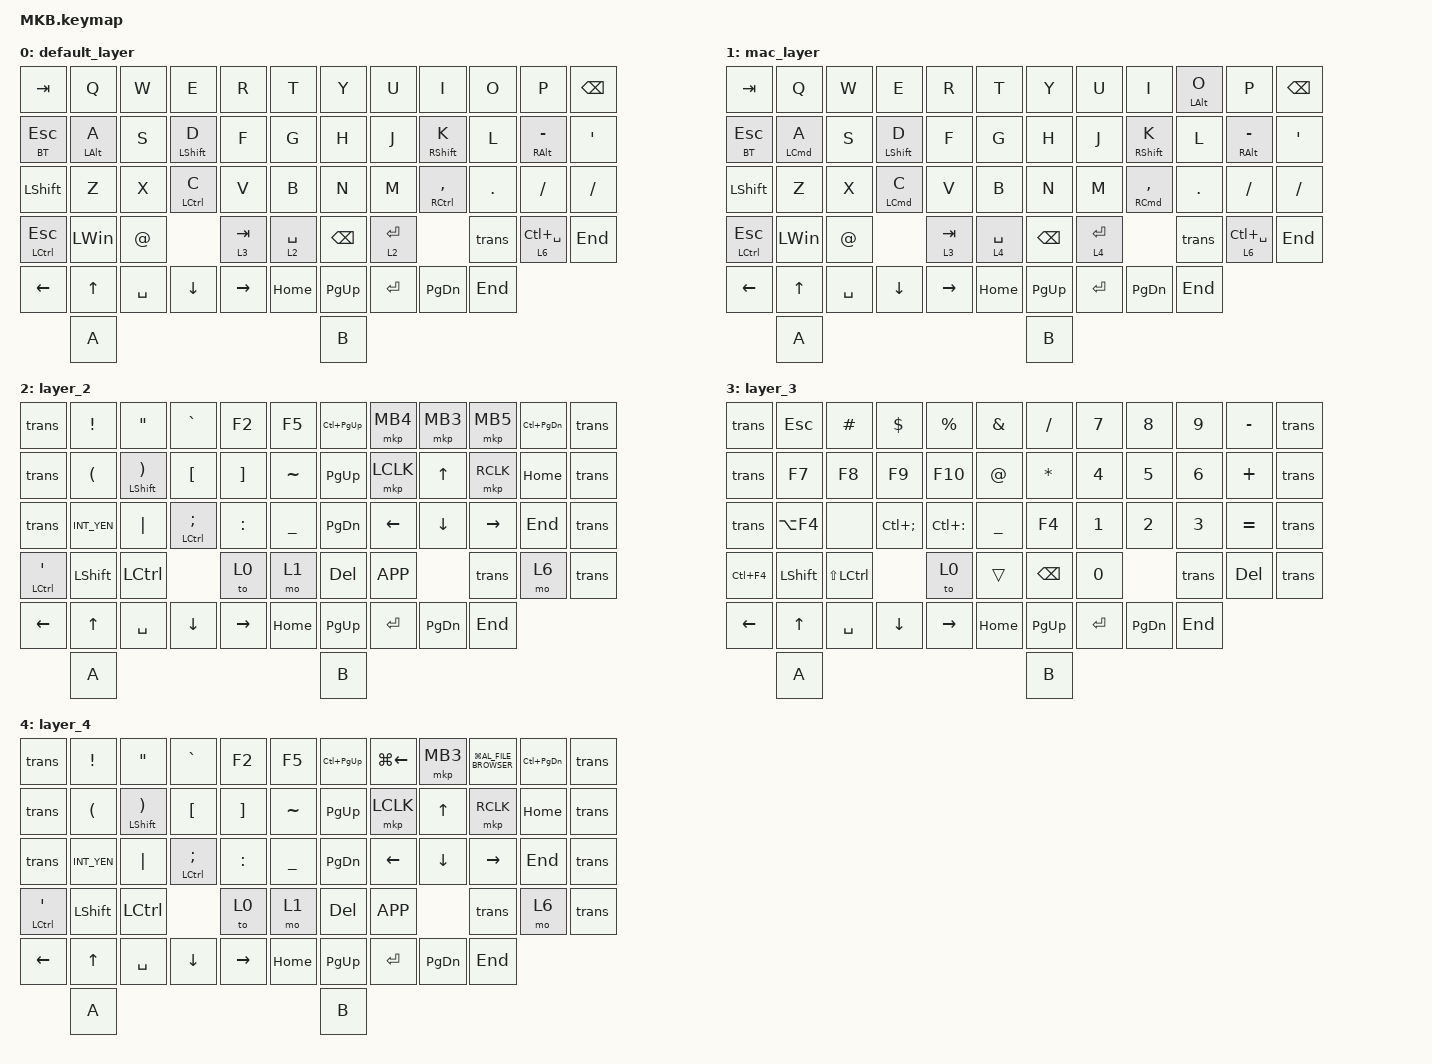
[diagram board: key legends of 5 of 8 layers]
// #include <layout_shift.dtsi>

#include <layout_shift_kp_override.dtsi>
#include <behaviors.dtsi>
#include <dt-bindings/zmk/bt.h>
#include <dt-bindings/zmk/keys.h>
#include <dt-bindings/zmk/pointing.h>
#include <input/processors.dtsi>

// スクロール量を変更

#define ZMK_POINTING_DEFAULT_SCRL_VAL 100
#define MOUSE 5
#define SCROLL 6
#define BT 7

&mt {
    flavor = "balanced";
    quick-tap-ms = <0>;
};

&mkp_input_listener { input-processors = <&zip_temp_layer 5 10000>; };

/ {
    combos { compatible = "zmk,combos"; };

    macros {
        to_layer_0: to_layer_0 {
            compatible = "zmk,behavior-macro-one-param";
            #binding-cells = <1>;
            bindings = <&to 0 &macro_param_1to1 &kp MACRO_PLACEHOLDER>;
            label = "TO_LAYER_0";
        };

        exit_AML: exit_AML {
            compatible = "zmk,behavior-macro";
            wait-ms = <0>;
            tap-ms = <0>;
            #binding-cells = <0>;
            bindings = <&tog_off MOUSE>;
            label = "exit_AML";
        };

        kp_exit_AML: kp_exit_AML {
            compatible = "zmk,behavior-macro-one-param";
            wait-ms = <0>;
            tap-ms = <0>;
            #binding-cells = <1>;
            bindings = <&macro_param_1to1 &kp MACRO_PLACEHOLDER &exit_AML>;
            label = "KP_exit_AML";
        };

        bt0_win: bt0_win {
            compatible = "zmk,behavior-macro";
            #binding-cells = <0>;
            bindings =
                <&tog_off 1>,
                <&macro_wait_time 100>,
                <&bt BT_SEL 0>,
                <&macro_wait_time 500>;

            label = "BT0_WN";
        };

        bt1_win: bt1_win {
            compatible = "zmk,behavior-macro";
            #binding-cells = <0>;
            bindings =
                <&tog_off 1>,
                <&macro_wait_time 200>,
                <&bt BT_SEL 1>,
                <&macro_wait_time 500>;

            label = "BT1_WIN";
        };

        bt2_mac: bt2_mac {
            compatible = "zmk,behavior-macro";
            #binding-cells = <0>;
            bindings =
                <&tog_off 1>,
                <&macro_wait_time 200>,
                <&bt BT_SEL 2>,
                <&macro_wait_time 500>,
                <&tog_on 1>;

            label = "BT1";
        };

        bt3_mac: bt3_mac {
            compatible = "zmk,behavior-macro";
            #binding-cells = <0>;
            bindings =
                <&tog_off 1>,
                <&macro_wait_time 200>,
                <&bt BT_SEL 3>,
                <&macro_wait_time 500>,
                <&tog_on 1>;

            label = "BT3_WIN";
        };

        bt4_win: bt4_win {
            compatible = "zmk,behavior-macro";
            #binding-cells = <0>;
            bindings =
                <&tog_off 1>,
                <&macro_wait_time 200>,
                <&bt BT_SEL 4>,
                <&macro_wait_time 500>;

            label = "BT4_WIN";
        };
    };

    behaviors {
        lt_to_layer_0: lt_to_layer_0 {
            compatible = "zmk,behavior-hold-tap";
            label = "LAYER_TAP_TO_0";
            bindings = <&mo>, <&to_layer_0>;

            #binding-cells = <2>;
            tapping-term-ms = <200>;
        };

        // 新しいスクロール動作

        scroll_up_down: behavior_sensor_rotate_mouse_wheel_up_down {
            compatible = "zmk,behavior-sensor-rotate";
            #sensor-binding-cells = <0>;
            bindings = <&msc SCRL_UP>, <&msc SCRL_DOWN>;

            // 追加: スクロールのタップ時間を設定 (20ms)

            tap-ms = <20>;
        };

        tog_on: toggle_layer_on {
            compatible = "zmk,behavior-toggle-layer";
            #binding-cells = <1>;
            display-name = "Toggle Layer On";
            toggle-mode = "on";
        };

        tog_off: toggle_layer_off {
            compatible = "zmk,behavior-toggle-layer";
            #binding-cells = <1>;
            display-name = "Toggle Layer Off";
            toggle-mode = "off";
        };

        mt_exit_AML_on_tap: mt_exit_AML_on_tap {
            compatible = "zmk,behavior-hold-tap";
            label = "MT_exit_AML_ON_TAP";
            bindings = <&kp>, <&kp_exit_AML>;

            #binding-cells = <2>;
            tapping-term-ms = <200>;
            flavor = "balanced";
            quick-tap-ms = <200>;
        };
    };
};
/ {
    keymap {
        compatible = "zmk,keymap";

        default_layer {
            bindings = <
&kp TAB                           &kp Q           &kp W   &kp E               &kp R        &kp T          &kp Y          &kp U        &kp I                    &kp O     &kp P                &kp BACKSPACE
&lt BT ESC                        &mt LEFT_ALT A  &kp S   &mt LEFT_SHIFT D    &kp F        &kp G          &kp H          &kp J        &mt RIGHT_SHIFT K        &kp L     &mt RIGHT_ALT MINUS  &kp SQT
&kp LSHFT                         &kp Z           &kp X   &mt LEFT_CONTROL C  &kp V        &kp B          &kp N          &kp M        &mt RIGHT_CONTROL COMMA  &kp DOT   &kp SLASH            &kp FSLH
&mt_exit_AML_on_tap LCTRL ESCAPE  &kp LEFT_WIN    &kp AT                      &lt 3 TAB    &lt 2 SPACE    &kp BACKSPACE  &lt 2 ENTER                           &kp trans &lt 6 LC(SPACE)      &kp END
&kp LEFT      &kp UP    &kp SPACE  &kp DOWN  &kp RIGHT                                          &kp HOME       &kp PG_UP  &kp ENTER  &kp PG_DN  &kp END
                                   &kp A                                                                       &kp B
             >;

            sensor-bindings = <&scroll_up_down>;
        };

        mac_layer {
            bindings = <
&kp TAB                           &kp Q                &kp W         &kp E               &kp R      &kp T        &kp Y             &kp U  &kp I                    &mt LEFT_ALT O  &kp P                &kp BACKSPACE
&lt BT ESC                        &mt LEFT_COMMAND A   &kp S         &mt LEFT_SHIFT D    &kp F      &kp G        &kp H             &kp J  &mt RIGHT_SHIFT K        &kp L           &mt RIGHT_ALT MINUS  &kp SQT
&kp LSHFT                         &kp Z                &kp X         &mt LEFT_COMMAND C  &kp V      &kp B        &kp N             &kp M  &mt RIGHT_COMMAND COMMA  &kp DOT         &kp SLASH            &kp FSLH
&mt_exit_AML_on_tap LCTRL ESCAPE  &kp LEFT_WIN         &kp AT                            &lt 3 TAB  &lt 4 SPACE  &kp BACKSPACE     &lt 4 ENTER                     &kp trans       &lt 6 LC(SPACE)      &kp END
&kp LEFT   &kp UP     &kp SPACE  &kp DOWN   &kp RIGHT                            &kp HOME   &kp PG_UP  &kp ENTER  &kp PG_DN  &kp END
                                 &kp A                                                      &kp B
            >;

            sensor-bindings = <&scroll_up_down>;
        };

        layer_2 {
            bindings = <
&kp trans                                      &kp EXCL                                       &kp DQT                                           &kp GRAVE                   &kp F2             &kp F5                               &kp LC(PAGE_UP)  &mkp MB4   &mkp MB3        &mkp MB5   &kp LC(PAGE_DOWN) &kp trans 
&kp trans                                      &kp LEFT_PARENTHESIS                           &mt_exit_AML_on_tap LEFT_SHIFT RIGHT_PARENTHESIS  &kp LEFT_BRACKET            &kp RIGHT_BRACKET  &kp TILDE         &kp PAGE_UP      &mkp LCLK  &kp UP_ARROW    &mkp RCLK  &kp HOME &kp trans 
&kp trans                                      &kp INT_YEN                                    &kp PIPE                                          &mt LEFT_CONTROL SEMICOLON  &kp COLON          &kp UNDERSCORE    &kp PAGE_DOWN    &kp LEFT   &kp DOWN_ARROW  &kp RIGHT  &kp END &kp trans 
&mt_exit_AML_on_tap LEFT_CONTROL SINGLE_QUOTE  &kp LEFT_SHIFT                                 &kp LEFT_CONTROL            &to 0              &mo 1           &kp DELETE  &kp K_APP                                           &kp trans    &mo 6 &kp trans 
&kp LEFT      &kp UP    &kp SPACE  &kp DOWN  &kp RIGHT                                          &kp HOME       &kp PG_UP  &kp ENTER  &kp PG_DN  &kp END
                                   &kp A                                                                       &kp B
            >;

            sensor-bindings = <&inc_dec_kp C_VOL_UP C_VOLUME_DOWN>;
        };

        layer_3 {
            bindings = <
&kp trans &kp ESCAPE  &kp HASH        &kp DOLLAR            &kp PERCENT    &kp AMPERSAND                            &kp SLASH     &kp N7        &kp N8        &kp N9        &kp MINUS &kp trans 
&kp trans &kp F7      &kp F8          &kp F9                &kp F10        &kp AT                 &kp ASTERISK  &kp NUMBER_4  &kp N5        &kp NUMBER_6  &kp PLUS &kp trans 
&kp trans &kp LA(F4)  &none           &kp LC(SEMICOLON)     &kp LC(COLON)  &kp UNDERSCORE         &kp F4        &kp NUMBER_1  &kp NUMBER_2  &kp NUMBER_3  &kp EQUAL &kp trans 
&kp LC(F4)  &kp LEFT_SHIFT  &kp LS(LEFT_CONTROL)  &to 0          &trans           &kp BACKSPACE  &kp N0                                                &kp trans   &kp DELETE &kp trans 
&kp LEFT      &kp UP    &kp SPACE  &kp DOWN  &kp RIGHT                                          &kp HOME       &kp PG_UP  &kp ENTER  &kp PG_DN  &kp END
                                   &kp A                                                                       &kp B
            >;

            sensor-bindings = <&inc_dec_kp PAGE_UP PAGE_DOWN>;
        };

        layer_4 {
            bindings = <
&kp trans &kp EXCL                                       &kp DQT                                           &kp GRAVE                   &kp F2             &kp F5                               &kp LC(PAGE_UP)  &kp LG(LEFT_ARROW)  &mkp MB3        &kp LG(C_AL_FILE_BROWSER)  &kp LC(PAGE_DOWN) &kp trans 
&kp trans &kp LEFT_PARENTHESIS                           &mt_exit_AML_on_tap LEFT_SHIFT RIGHT_PARENTHESIS  &kp LEFT_BRACKET            &kp RIGHT_BRACKET  &kp TILDE          &kp PAGE_UP      &mkp LCLK           &kp UP_ARROW    &mkp RCLK                  &kp HOME &kp trans 
&kp trans &kp INT_YEN                                    &kp PIPE                                          &mt LEFT_CONTROL SEMICOLON  &kp COLON          &kp UNDERSCORE     &kp PAGE_DOWN    &kp LEFT            &kp DOWN_ARROW  &kp RIGHT                  &kp END &kp trans 
&mt_exit_AML_on_tap LEFT_CONTROL SINGLE_QUOTE  &kp LEFT_SHIFT                                    &kp LEFT_CONTROL            &to 0              &mo 1           &kp DELETE  &kp K_APP                                                                   &kp trans     &mo 6 &kp trans 
&kp LEFT      &kp UP    &kp SPACE  &kp DOWN  &kp RIGHT                                          &kp HOME       &kp PG_UP  &kp ENTER  &kp PG_DN  &kp END
                                   &kp A                                                                       &kp B
            >;

            sensor-bindings = <&inc_dec_kp C_VOL_UP C_VOLUME_DOWN>;
        };

        MOUSE {
            bindings = <
&none &none  &none  &none  &none   &none                   &none  &none      &none  &none      &none &none 
&none &none  &none  &none  &none   &none    &none  &mkp LCLK  &none  &mkp RCLK  &none &none 
&none &none  &none  &none  &none   &none    &none  &none      &none  &none      &none &none 
&none &none  &none  &none  &tog 0  &trans   &none  &none                     &none  &none  &none
&kp LEFT      &kp UP    &kp SPACE  &kp DOWN  &kp RIGHT                                          &kp HOME       &kp PG_UP  &kp ENTER  &kp PG_DN  &kp END
                                   &kp A                                                                       &kp B
            >;
        };

        //        MOUSE {
        //            bindings = <
        //&trans  &trans  &trans  &trans  &trans                         &trans  &trans     &trans     &trans     &trans
        //&trans  &trans  &trans  &trans  &trans  &trans    &trans       &trans  &mkp LCLK  &mkp MCLK  &mkp RCLK  &trans
        //&trans  &trans  &trans  &trans  &trans  &trans    &bootloader  &trans  &trans     &trans     &trans     &trans
        //&trans  &trans  &trans  &trans  &trans  &trans    &trans       &trans                                   &trans
        //            >;
        //
        //            sensor-bindings = <&inc_dec_kp K_SCROLL_UP K_SCROLL_DOWN>;
        //        };

        SCROLL {
            bindings = <
&none &trans  &trans  &trans  &trans  &trans    &trans  &trans  &trans  &trans  &trans &none 
&none &trans  &trans  &trans  &trans  &trans   &trans  &trans  &trans  &trans  &trans &none 
&none &trans  &trans  &trans  &trans  &trans   &trans  &trans  &trans  &trans  &trans &none 
&trans  &trans  &trans  &tog 0  &trans  &trans    &trans  &trans                       &none    &trans &none 
&kp LEFT      &kp UP    &kp SPACE  &kp DOWN  &kp RIGHT                                          &kp HOME       &kp PG_UP  &kp ENTER  &kp PG_DN  &kp END
                                   &kp A                                                                       &kp B
            >;
        };

        BT {
            bindings = <
&none &bt0_win        &bt1_win  &bt2_mac  &bt3_mac  &bt4_win  &bt0_win  &bt1_win  &bt2_mac  &bt3_mac  &bt4_win &none 
&none &none           &none     &none     &none     &none     &none     &none     &none     &none     &none &none 
&none &bt BT_CLR      &none     &none     &none     &none     &none     &none     &none     &none     &bt BT_CLR &none 
&bt BT_CLR_ALL  &none     &none     &tog 0    &trans    &mo 6    &none  &none                      &none              &bt BT_CLR_ALL &none 
&kp LEFT      &kp UP    &kp SPACE  &kp DOWN  &kp RIGHT                                          &kp HOME       &kp PG_UP  &kp ENTER  &kp PG_DN  &kp END
                                   &kp A                                                                       &kp B
            >;
        };
    };
};

